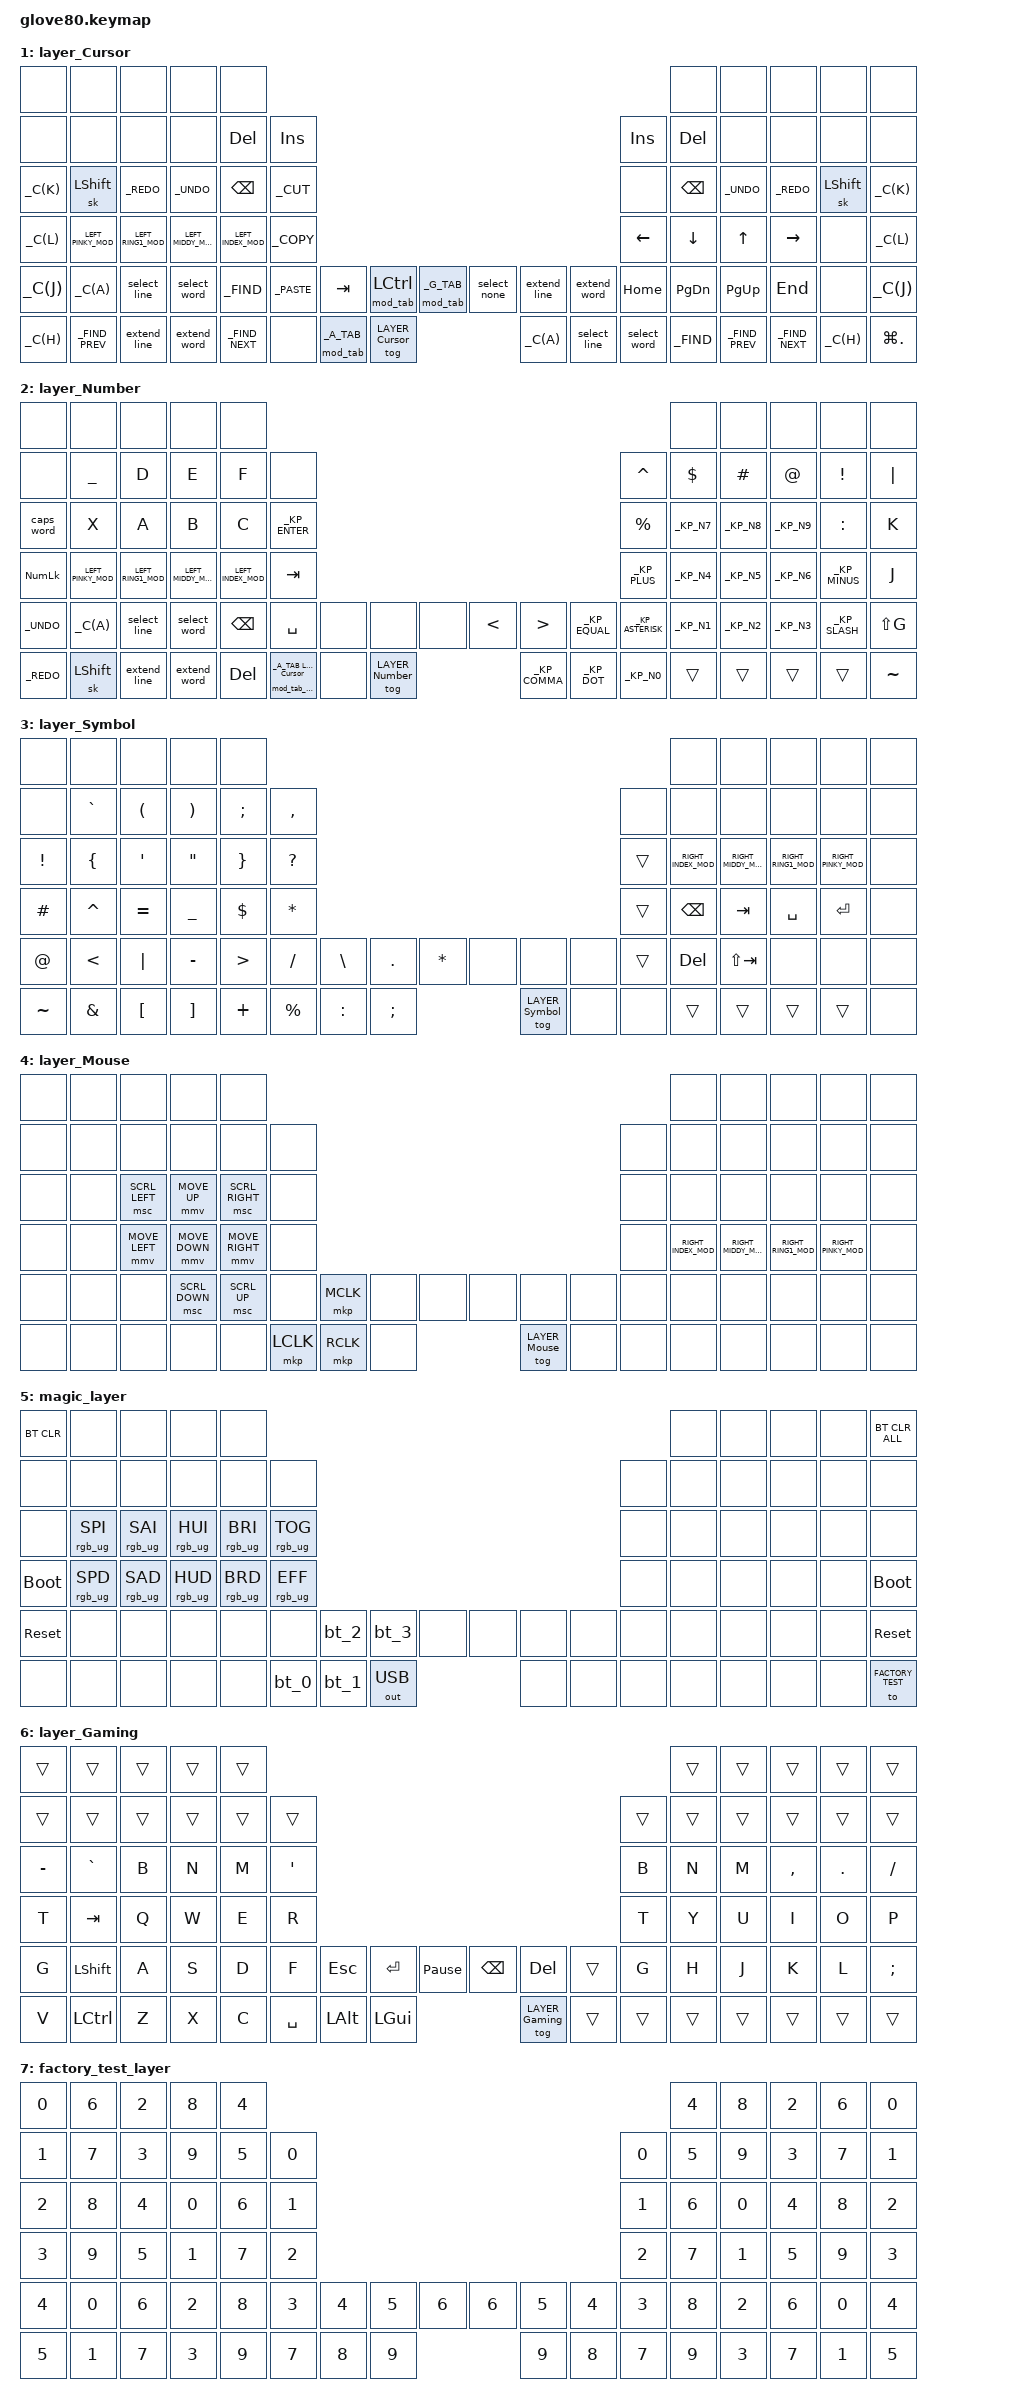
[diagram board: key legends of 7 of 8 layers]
/*
 * Copyright (c) 2020 The ZMK Contributors
 *
 * SPDX-License-Identifier: MIT
 */

#include <behaviors.dtsi>
#include <dt-bindings/zmk/keys.h>
#include <dt-bindings/zmk/bt.h>
#include <dt-bindings/zmk/ext_power.h>
#include <dt-bindings/zmk/outputs.h>
#include <dt-bindings/zmk/rgb.h>
#include <dt-bindings/zmk/mouse.h>


#define HYPER LC(LS(LG(LALT)))

// layers
#define DEFAULT 0
#define LOWER 1
#define MAGIC 2
#define FACTORY_TEST 3

// custom keycodes
#define LEFT_PINKY_MOD LGUI
#define LEFT_RING1_MOD LALT
#define LEFT_MIDDY_MOD LCTL
#define LEFT_INDEX_MOD LSFT
#define RIGHT_PINKY_MOD RGUI
#define RIGHT_RING1_MOD RALT
#define RIGHT_MIDDY_MOD RCTL
#define RIGHT_INDEX_MOD RSFT
#define _C          LG
#define _UNDO       _C(Z)
#define _REDO       _C(Y)
#define _CUT        _C(X)
#define _COPY       _C(C)
#define _PASTE      _C(V)
#define _FIND       _C(F)
#define _FIND_NEXT  _C(G)
#define _FIND_PREV  _C(LS(G))
#define BSPC_CURSOR &lt layer_Cursor BSPC
#define DEL_NUMBER &lt layer_Number DEL
#define SPACE_SYMBOL &lt layer_Symbol SPACE
#define RET_MOUSE &lt layer_Mouse RET

/ {
    behaviors {
        // For the "layer" key, it'd nice to be able to use it as either a shift or a toggle.
        // Configure it as a tap dance, so the first tap (or hold) is a &mo and the second tap is a &to
        layer_td: tap_dance_0 {
            compatible = "zmk,behavior-tap-dance";
            label = "LAYER_TAP_DANCE";
            #binding-cells = <0>;
            tapping-term-ms = <200>;
            bindings = <&mo LOWER>, <&to LOWER>;
        };

        magic: magic_hold_tap {
            compatible = "zmk,behavior-hold-tap";
            label = "MAGIC_HOLD_TAP";
            #binding-cells = <2>;
            flavor = "tap-preferred";
            tapping-term-ms = <200>;
            bindings = <&mo>, <&rgb_ug_status_macro>;
        };
    };

    macros {
        rgb_ug_status_macro: rgb_ug_status_macro_0 {
            label = "RGB_UG_STATUS";
            compatible = "zmk,behavior-macro";
            #binding-cells = <0>;
            bindings
                = <&rgb_ug RGB_STATUS>;
        };

        bt_0: bt_profile_macro_0 {
            label = "BT_0";
            compatible = "zmk,behavior-macro";
            #binding-cells = <0>;
            bindings
                = <&out OUT_BLE>,
                  <&bt BT_SEL 0>;
        };

        bt_1: bt_profile_macro_1 {
            label = "BT_1";
            compatible = "zmk,behavior-macro";
            #binding-cells = <0>;
            bindings
                = <&out OUT_BLE>,
                  <&bt BT_SEL 1>;
        };

        bt_2: bt_profile_macro_2 {
            label = "BT_2";
            compatible = "zmk,behavior-macro";
            #binding-cells = <0>;
            bindings
                = <&out OUT_BLE>,
                  <&bt BT_SEL 2>;
        };

        bt_3: bt_profile_macro_3 {
            label = "BT_3";
            compatible = "zmk,behavior-macro";
            #binding-cells = <0>;
            bindings
                = <&out OUT_BLE>,
                  <&bt BT_SEL 3>;
        };

        //////////////////////////////////////////////////////////////////////////
        //
        // Approximation of Pascal Getreuer's Select Word macro from QMK
        // - https://getreuer.info/posts/keyboards/select-word/index.html
        //
        //////////////////////////////////////////////////////////////////////////

        //
        // SELECT_WORD_DELAY defines how long the macro waits (milliseconds)
        // after moving the cursor before it selects a word.  A larger delay
        // may allow the macro to move to the next word upon each invocation.
        //
        #ifndef SELECT_WORD_DELAY
        #define SELECT_WORD_DELAY 1
        #endif

        ZMK_MACRO(select_none,
            wait-ms = <SELECT_WORD_DELAY>;
            tap-ms = <SELECT_WORD_DELAY>;
            bindings = <&kp DOWN &kp UP &kp RIGHT &kp LEFT>;
        )

        //
        // select a word (jumps to next word upon each successive invocation)
        //
        select_word: select_word {
            compatible = "zmk,behavior-mod-morph";
            #binding-cells = <0>;
            bindings = <&select_word_right>, <&select_word_left>;
            mods = <(MOD_LSFT|MOD_RSFT)>;
        };
        ZMK_MACRO(select_word_right,
            wait-ms = <SELECT_WORD_DELAY>;
            tap-ms = <SELECT_WORD_DELAY>;
            bindings = <&kp _W(RIGHT) &kp _W(LEFT) &kp _W(LS(RIGHT))>;
        )
        ZMK_MACRO(select_word_left,
            wait-ms = <SELECT_WORD_DELAY>;
            tap-ms = <SELECT_WORD_DELAY>;
            bindings = <&kp _W(LEFT) &kp _W(RIGHT) &kp _W(LS(LEFT))>;
        )

        //
        // extend current selection by one word
        //
        extend_word: extend_word {
            compatible = "zmk,behavior-mod-morph";
            #binding-cells = <0>;
            bindings = <&extend_word_right>, <&extend_word_left>;
            mods = <(MOD_LSFT|MOD_RSFT)>;
        };
        ZMK_MACRO(extend_word_right,
            wait-ms = <SELECT_WORD_DELAY>;
            tap-ms = <SELECT_WORD_DELAY>;
            bindings = <&kp _W(LS(RIGHT))>;
        )
        ZMK_MACRO(extend_word_left,
            wait-ms = <SELECT_WORD_DELAY>;
            tap-ms = <SELECT_WORD_DELAY>;
            bindings = <&kp _W(LS(LEFT))>;
        )

        //
        // select current line
        //
        select_line: select_line {
            compatible = "zmk,behavior-mod-morph";
            #binding-cells = <0>;
            bindings = <&select_line_right>, <&select_line_left>;
            mods = <(MOD_LSFT|MOD_RSFT)>;
        };
        ZMK_MACRO(select_line_right,
            wait-ms = <SELECT_WORD_DELAY>;
            tap-ms = <SELECT_WORD_DELAY>;
            bindings = <&kp _HOME &kp LS(_END)>;
        )
        ZMK_MACRO(select_line_left,
            wait-ms = <SELECT_WORD_DELAY>;
            tap-ms = <SELECT_WORD_DELAY>;
            bindings = <&kp _END &kp LS(_HOME)>;
        )

        //
        // extend current selection by one line
        //
        extend_line: extend_line {
            compatible = "zmk,behavior-mod-morph";
            #binding-cells = <0>;
            bindings = <&extend_line_right>, <&extend_line_left>;
            mods = <(MOD_LSFT|MOD_RSFT)>;
        };
        ZMK_MACRO(extend_line_right,
            wait-ms = <SELECT_WORD_DELAY>;
            tap-ms = <SELECT_WORD_DELAY>;
            bindings = <&kp LS(DOWN) &kp LS(_END)>;
        )
        ZMK_MACRO(extend_line_left,
            wait-ms = <SELECT_WORD_DELAY>;
            tap-ms = <SELECT_WORD_DELAY>;
            bindings = <&kp LS(UP) &kp LS(_HOME)>;
        )


    };

combos {
    compatible = "zmk,combos";
    combo_caps_word {
        timeout-ms = <50>;
        key-positions = <52 57>;
        bindings = <&kp &caps_word>;
    };
};


    keymap {
        compatible = "zmk,keymap";

        default_layer {
            // ---------------------------------------------------------------------------------------------------------------------------------
            // |  F1   |  F2 |  F3 |  F4  |  F5  |                                                               |  F6   |  F7   |  F8  |   F9  |  F10 |
            // |  =    |  1  |  2  |  3   |  4   |  5   |                                                 |  6   |   7   |   8   |  9   |   0   |   -  |
            // |  TAB  |  Q  |  W  |  E   |  R   |  T   |                                                 |  Y   |   U   |   I   |  O   |   P   |   \  |
            // |  ESC  |  A  |  S  |  D   |  F   |  G   |                                                 |  H   |   J   |   K   |  L   |   ;   |   '  |
            // |   `   |  Z  |  X  |  C   |  V   |  B   | LSHFT | LCTRL | LOWER | | LGUI  | RCTRL | RSHFT |  N   |   M   |   ,   |  .   |   /   | PGUP |
            // | MAGIC | HOME| END | LEFT | RIGHT|      | BSPC  | DEL   | LALT  | | RALT  | RET   | SPACE |      |  UP   | DOWN  |  [   |   ]   | PGDN |

            bindings = <
            &kp F1         &kp F2   &kp F3      &kp F4      &kp F5                                                                                         &kp F6  &kp F7      &kp F8      &kp F9      &kp F10
            &kp EQUAL      &kp N1   &kp N2      &kp N3      &kp N4      &kp N5                                                                     &kp N6  &kp N7  &kp N8      &kp N9      &kp N0      &kp MINUS
            &kp ESC        &kp Q    &kp W       &kp E       &kp R       &kp T                                                                      &kp Y   &kp U   &kp I       &kp O       &kp P       &kp BSLH
            &none        &kp A    &kp S       &kp D       &kp F       &kp G                                                                      &kp H   &kp J   &kp K       &kp L       &kp SEMI    &kp SQT
            &kp GRAVE      &kp Z    &kp X       &kp C       &kp V       &kp B   &kp LSHFT   &kp LCTRL   &kp LGUI  &kp LALT  &kp RCTRL &kp RSHFT   &kp N   &kp M   &kp COMMA   &kp DOT     &kp FSLH    &kp LBKT
            &magic MAGIC 0 &kp HOME &kp PG_DN     &kp PG_UP    &kp END           &kp BSPC_CURSOR    &kp DEL_NUMBER     &key_repeat &kp TAB  &kp RET_MOUSE   &kp SPACE_SYMBOL           &kp LEFT  &kp DOWN    &kp UP    &kp RIGHT    &kp RBKT
            >;
        };

        layer_Cursor {
            bindings = <
            &none               &none               &none               &none               &none                                                                                                                     &none           &none           &none      &none        &none
            &none               &none               &none               &none             &kp DEL     &kp INS                                                                                            &kp INS    &kp DEL           &none           &none      &none        &none
            &kp _C(K)           &sk LSHFT           &kp _REDO           &kp _UNDO            &kp BSPC    &kp _CUT                                                                                           &none   &kp BSPC       &kp _UNDO       &kp _REDO  &sk LSHFT    &kp _C(K)
            &kp _C(L)  &kp LEFT_PINKY_MOD  &kp LEFT_RING1_MOD  &kp LEFT_MIDDY_MOD  &kp LEFT_INDEX_MOD   &kp _COPY                                                                                          &kp LEFT          &kp DOWN        &kp UP  &kp RIGHT &none  &kp _C(L)
            &kp _C(J)           &kp _C(A)        &select_line        &select_word           &kp _FIND  &kp _PASTE  &kp TAB    &mod_tab LCTL    &mod_tab _G_TAB  &select_none  &extend_line  &extend_word  &kp HOME       &kp PG_DN       &kp PG_UP    &kp END  &none    &kp _C(J)
            &kp _C(H)      &kp _FIND_PREV        &extend_line        &extend_word      &kp _FIND_NEXT                &none  &mod_tab _A_TAB  &tog LAYER_Cursor     &kp _C(A)  &select_line  &select_word              &kp _FIND  &kp _FIND_PREV  &kp _FIND_NEXT  &kp _C(H)  &kp LG(DOT)
            >;
        };

        layer_Number {
            bindings = <
            &none               &none               &none               &none               &none                                                                                                                                                  &none       &none       &none          &none      &none
            &none           &kp UNDER               &kp D               &kp E               &kp F          &none                                                                                                                   &kp CARET    &kp DLLR    &kp HASH      &kp AT       &kp EXCL   &kp PIPE
            &caps_word               &kp X               &kp A               &kp B               &kp C  &kp _KP_ENTER                                                                                                                   &kp PRCNT  &kp _KP_N7  &kp _KP_N8  &kp _KP_N9      &kp COLON      &kp K
            &kp KP_NUM  &kp LEFT_PINKY_MOD  &kp LEFT_RING1_MOD  &kp LEFT_MIDDY_MOD  &kp LEFT_INDEX_MOD        &kp TAB                                                                                                                &kp _KP_PLUS  &kp _KP_N4  &kp _KP_N5  &kp _KP_N6  &kp _KP_MINUS      &kp J
            &kp _UNDO           &kp _C(A)        &select_line        &select_word            &kp BSPC      &kp SPACE                               &none   &none              &none         &kp LT       &kp GT  &kp _KP_EQUAL  &kp _KP_ASTERISK  &kp _KP_N1  &kp _KP_N2  &kp _KP_N3  &kp _KP_SLASH  &kp LS(G)
            &kp _REDO           &sk LSHFT        &extend_line        &extend_word             &kp DEL                 &mod_tab_chord _A_TAB LAYER_Cursor   &none  &tog LAYER_Number  &kp _KP_COMMA  &kp _KP_DOT     &kp _KP_N0                        &trans      &trans      &trans         &trans  &kp TILDE
            >;
        };

        layer_Symbol {
            bindings = <
            &none      &none      &none      &none     &none                                                                                                      &none                &none                &none                &none   &none
            &none  &kp GRAVE   &kp LPAR   &kp RPAR  &kp SEMI  &kp COMMA                                                                      &none                &none                &none                &none                &none   &none
            &kp EXCL   &kp LBRC    &kp SQT    &kp DQT  &kp RBRC  &kp QMARK                                                                     &trans  &kp RIGHT_INDEX_MOD  &kp RIGHT_MIDDY_MOD  &kp RIGHT_RING1_MOD  &kp RIGHT_PINKY_MOD   &none
            &kp HASH  &kp CARET  &kp EQUAL  &kp UNDER  &kp DLLR   &kp STAR                                                                     &trans             &kp BSPC              &kp TAB            &kp SPACE              &kp RET   &none
            &kp AT     &kp LT   &kp PIPE  &kp MINUS    &kp GT   &kp FSLH   &kp BSLH    &kp DOT  &kp STAR              &none   &none   &none  &trans              &kp DEL          &kp LS(TAB)                &none                &none   &none
            &kp TILDE   &kp AMPS   &kp LBKT   &kp RBKT  &kp PLUS             &kp PRCNT  &kp COLON  &kp SEMI  &tog LAYER_Symbol   &none   &none                       &trans               &trans               &trans               &trans   &none
            >;
        };

        layer_Mouse {
            bindings = <
            &none   &none           &none           &none            &none                                                                                                &none                &none                &none                &none   &none
            &none   &none           &none           &none            &none   &none                                                                   &none                &none                &none                &none                &none   &none
            &none   &none  &msc SCRL_LEFT    &mmv MOVE_UP  &msc SCRL_RIGHT   &none                                                                   &none                &none                &none                &none                &none   &none
            &none   &none  &mmv MOVE_LEFT  &mmv MOVE_DOWN  &mmv MOVE_RIGHT   &none                                                                   &none  &kp RIGHT_INDEX_MOD  &kp RIGHT_MIDDY_MOD  &kp RIGHT_RING1_MOD  &kp RIGHT_PINKY_MOD   &none
            &none   &none           &none  &msc SCRL_DOWN     &msc SCRL_UP   &none  &mkp MCLK      &none   &none             &none   &none   &none   &none                &none                &none                &none                &none   &none
            &none   &none           &none           &none            &none          &mkp LCLK  &mkp RCLK   &none  &tog LAYER_Mouse   &none   &none                        &none                &none                &none                &none   &none
            >;
        };


        magic_layer {
            bindings = <
            &bt BT_CLR        &none               &none           &none           &none                                                                                                           &none      &none      &none      &none      &bt BT_CLR_ALL
            &none             &none               &none           &none           &none           &none                                                                                &none      &none      &none      &none      &none      &none
            &none             &rgb_ug RGB_SPI     &rgb_ug RGB_SAI &rgb_ug RGB_HUI &rgb_ug RGB_BRI &rgb_ug RGB_TOG                                                                      &none      &none      &none      &none      &none      &none
            &bootloader       &rgb_ug RGB_SPD     &rgb_ug RGB_SAD &rgb_ug RGB_HUD &rgb_ug RGB_BRD &rgb_ug RGB_EFF                                                                      &none      &none      &none      &none      &none      &bootloader
            &sys_reset        &none               &none           &none           &none           &none           &bt_2     &bt_3     &none            &none     &none     &none       &none      &none      &none      &none      &none      &sys_reset
            &none             &none               &none           &none           &none                           &bt_0     &bt_1     &out OUT_USB     &none     &none     &none                  &none      &none      &none      &none      &to FACTORY_TEST
            >;
        };

        layer_Gaming {
            bindings = <
            &trans     &trans  &trans  &trans  &trans                                                                                             &trans  &trans     &trans   &trans    &trans
            &trans     &trans  &trans  &trans  &trans   &trans                                                                            &trans  &trans  &trans     &trans   &trans    &trans
            &kp MINUS  &kp GRAVE   &kp B   &kp N   &kp M  &kp SQT                                                                             &kp B   &kp N   &kp M  &kp COMMA  &kp DOT  &kp FSLH
            &kp T    &kp TAB   &kp Q   &kp W   &kp E    &kp R                                                                             &kp T   &kp Y   &kp U      &kp I    &kp O     &kp P
            &kp G  &kp LSHFT   &kp A   &kp S   &kp D    &kp F    &kp ESC   &kp RET  &kp PAUSE_BREAK           &kp BSPC  &kp DEL  &trans   &kp G   &kp H   &kp J      &kp K    &kp L  &kp SEMI
            &kp V  &kp LCTRL   &kp Z   &kp X   &kp C           &kp SPACE  &kp LALT         &kp LGUI  &tog LAYER_Gaming   &trans  &trans          &trans  &trans     &trans   &trans    &trans
            >;
        };

        factory_test_layer {
            bindings = <
            &kp N0   &kp N6   &kp N2   &kp N8   &kp N4                                                                              &kp N4   &kp N8   &kp N2   &kp N6   &kp N0
            &kp N1   &kp N7   &kp N3   &kp N9   &kp N5   &kp N0                                                            &kp N0   &kp N5   &kp N9   &kp N3   &kp N7   &kp N1
            &kp N2   &kp N8   &kp N4   &kp N0   &kp N6   &kp N1                                                            &kp N1   &kp N6   &kp N0   &kp N4   &kp N8   &kp N2
            &kp N3   &kp N9   &kp N5   &kp N1   &kp N7   &kp N2                                                            &kp N2   &kp N7   &kp N1   &kp N5   &kp N9   &kp N3
            &kp N4   &kp N0   &kp N6   &kp N2   &kp N8   &kp N3   &kp N4   &kp N5   &kp N6      &kp N6   &kp N5   &kp N4   &kp N3   &kp N8   &kp N2   &kp N6   &kp N0   &kp N4
            &kp N5   &kp N1   &kp N7   &kp N3   &kp N9            &kp N7   &kp N8   &kp N9      &kp N9   &kp N8   &kp N7            &kp N9   &kp N3   &kp N7   &kp N1   &kp N5
            >;
        };
    };
};
